AUTOSAR XML (schema 4-2-2)
package /ComponentTypes
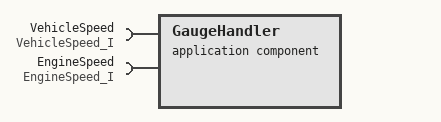
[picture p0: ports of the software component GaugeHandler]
  application sw component type GaugeHandler
    require port VehicleSpeed: nonqueued-receiver-com-spec{data-element=VehicleSpeed, filter=data-filter-type=ALWAYS, init-value=constant-reference=VehicleSpeed_IV}, required-interface=VehicleSpeed_I
    require port EngineSpeed: nonqueued-receiver-com-spec{data-element=EngineSpeed, filter=data-filter-type=ALWAYS, init-value=constant-reference=EngineSpeed_IV}, required-interface=EngineSpeed_I
    behavior GaugeHandler_InternalBehavior
      port-api-options:
        enable-take-address=false, indirect-api=false, port=EngineSpeed
        enable-take-address=false, indirect-api=false, port=VehicleSpeed
  swc implementation GaugeHandler_Implementation: behavior=GaugeHandler_InternalBehavior
    code-descriptors:
      code Default: artifact-descriptors=autosar-engineering-object={short-label=Default, category=SWSRC}
